# DSPIC33CK256MP506 register map
Vendor: Microchip
Registers are 24-bit, read-write, reset 0xFFFFFF unless marked. A register's access mark holds for its fields unless they carry their own. Addresses are absolute, and some are shared; only a register's first bit layout is shown; [hi:lo] are bit positions; {n}, {i} and the like mark numbered series; 'fields as' and 'values as' point back to an identical list.

## CONFIG — Configuration words, addresses in ProgramSpace
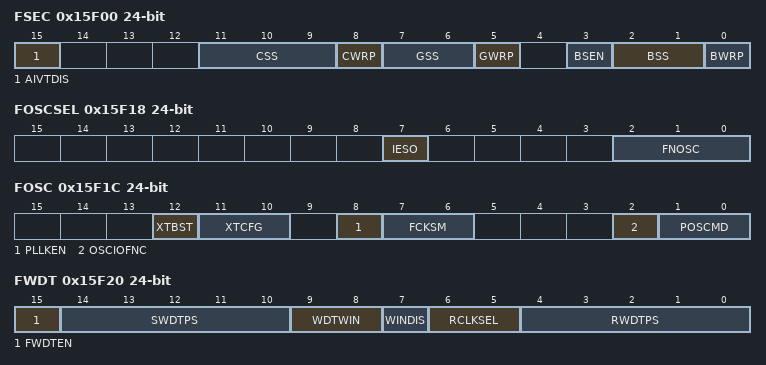
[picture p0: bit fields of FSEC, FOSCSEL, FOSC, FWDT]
0x15F00 FSEC — Security Configuration Options
  [15] AIVTDIS — Alternate Interrupt Vector Table bit
    1=OFF (Disabled AIVT); 0=ON (Enabled AIVT)
  [11:9] CSS — Configuration Segment Code-Protect Level bits
    7=DISABLED (No Protection (other than CWRP)); 6=STNDRD (Standard Security); 4=ENHNCD (Enhanced Security); 0b0xx=HIGH (High Security)
  [8] CWRP — Configuration Segment Write-Protect bit
    1=OFF (Configuration Segment may be written); 0=ON (Configuration Segment is write protected)
  [7:6] GSS — General Segment Code-Protect Level bits
    3=DISABLED (No Protection (other than GWRP)); 2=STNDRD (Standard Security); 0b0x=HIGH (High Security)
  [5] GWRP — General Segment Write-Protect bit
    1=OFF (General Segment may be written); 0=ON (General Segment is write protected)
  [3] BSEN — Boot Segment Control bit
    1=OFF (No Boot Segment); 0=ON (Boot Segment size determined by FBSLIM)
  [2:1] BSS — Boot Segment Code-Protect Level bits
    3=DISABLED (No Protection (other than BWRP)); 2=STNDRD (Standard Security); 0b0x=HIGH (High Security)
  [0] BWRP — Boot Segment Write-Protect bit
    1=OFF (Boot Segment may be written); 0=ON (Boot Segment is write protected)
0x15F10 FBSLIM — Boot Segment Limit Configuration
  [12:0] BSLIM — Boot Segment Flash Page Address Limit bits
0x15F14 FSIGN reset 0xFF7FFF — Sign Bit Configuration
0x15F18 FOSCSEL — Oscillator Configuration 1
  [7] IESO — Two-speed Oscillator Start-up Enable bit
    1=ON (Start up device with FRC, then switch to user-selected oscillator source); 0=OFF (Start up with user-selected oscillator source)
  [2:0] FNOSC — Oscillator Source Selection
    7=FRCDIVN (Internal Fast RC (FRC) Oscillator with postscaler); 6=BFRC (Back up Fast RC (BFRC) Oscillator); 5=LPRC (Low-Power RC Oscillator (LPRC)); 3=PRIPLL (Primary Oscillator with PLL module (XT + PLL, HS + PLL, EC + PLL)); 2=PRI (Primary Oscillator (XT, HS, EC)); 1=FRCPLL (Fast RC Oscillator with divide-by-N with PLL module (FRCPLL)); 0=FRC (Internal Fast RC (FRC))
0x15F1C FOSC — Oscillator Configuration 2
  [12] XTBST — XT Boost
    1=ENABLE (Boost the kick-start); 0=DISABLE (Default kick-start)
  [11:10] XTCFG — XT Config
    0=G0 (4-8 MHz crystals); 1=G1 (8-16 MHz crystals); 2=G2 (16-24 MHz crystals); 3=G3 (24-32 MHz crystals)
  [8] PLLKEN — PLL Lock Status Control
    1=ON (PLL lock signal will be used to disable PLL clock output if lock is lost); 0=OFF (PLL lock signal is not used; the PLL clock output will not be disabled if lock is lost)
  [7:6] FCKSM — Clock Switching Mode bits
    0b1x=CSDCMD (Both Clock switching and Fail-safe Clock Monitor are disabled); 1=CSECMD (Clock switching is enabled,Fail-safe Clock Monitor is disabled); 0=CSECME (Both Clock switching and Fail-safe Clock Monitor are enabled)
  [2] OSCIOFNC — OSC2 Pin Function bit
    1=OFF (OSC2 is clock output); 0=ON (OSC2 is general purpose digital I/O pin)
  [1:0] POSCMD — Primary Oscillator Mode Select bits
    3=NONE (Primary Oscillator disabled); 2=HS (HS Crystal Oscillator Mode); 1=XT (XT Crystal Oscillator Mode); 0=EC (EC (External Clock) Mode)
0x15F20 FWDT — Watch Dog Configuration
  [15] FWDTEN — Watchdog Timer Enable bit
    1=ON (WDT enabled in hardware); 0=ON_SW (WDT controlled via SW, use WDTCON.ON bit)
  [14:10] SWDTPS — Sleep Mode Watchdog Timer Post Scaler select bits
    0=PS1 (1:1); 1=PS2 (1:2); 2=PS4 (1:4); 3=PS8 (1:8); 4=PS16 (1:16); 5=PS32 (1:32); 6=PS64 (1:64); 7=PS128 (1:128); 8=PS256 (1:256); 9=PS512 (1:512); 10=PS1024 (1:1024); 11=PS2048 (1:2048); 12=PS4096 (1:4096); 13=PS8192 (1:8192); 14=PS16384 (1:16384); 15=PS32768 (1:32768); 16=PS65536 (1:65536); 17=PS131072 (1:131072); 18=PS262144 (1:262144); 19=PS524288 (1:524288); 20=PS1048576 (1:1048576); 21=PS2097152 (1:2097152); 22=PS4194304 (1:4194304); 23=PS8388608 (1:8388608); 24=PS16777216 (1:16777216); 25=PS33554432 (1:33554432); 26=PS67108864 (1:67108864); 27=PS134217728 (1:134217728); 28=PS268435456 (1:268435456); 29=PS536870912 (1:536870912); 30=PS1073741824 (1:1073741824); 31=PS2147483648 (1:2147483648)
  [9:8] WDTWIN — Watchdog Timer Window Select bits
    3=WIN25 (WDT Window is 25% of WDT period); 2=WIN37 (WDT Window is 37.5% of WDT period); 1=WIN50 (WDT Window is 50% of WDT period); 0=WIN75 (WDT Windo is 75% of WDT period)
  [7] WINDIS — Watchdog Timer Window Enable bit
    1=ON (Watchdog Timer operates in Non-Window mode); 0=OFF (Watchdog Timer operates in Window mode)
  [6:5] RCLKSEL — Watchdog Timer Clock Select bits
    3=LPRC (Always use LPRC); 2=FRC (Use FRC when WINDIS = 0, system clock is not INTOSC/LPRC and device is not in Sleep;otherwise, use INTOSC/LPRC); 1=FCY (Use peripheral clk when system clock is not INTOSC/LPRC and device is not in Sleep;otherwise, use INTOSC/LPRC)
  [4:0] RWDTPS — Run Mode Watchdog Timer Post Scaler select bits
    values as SWDTPS
0x15F24 FPOR — Power On Configuration
  [6] BISTDIS — Memory BIST Feature Disable
    1=DISABLED (mBIST on reset feature disabled); 0=ENABLED (mBIST on reset feature enabled)
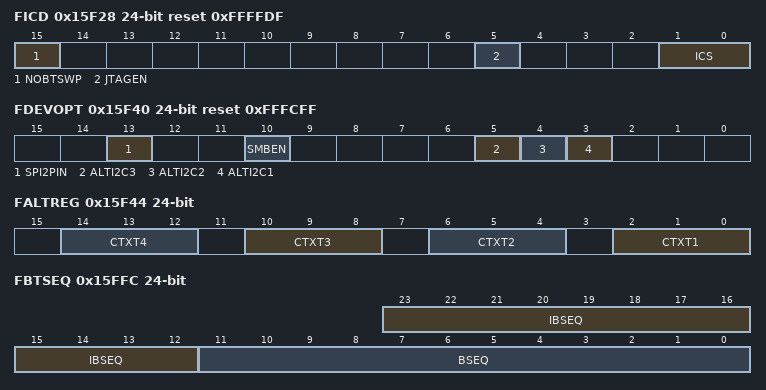
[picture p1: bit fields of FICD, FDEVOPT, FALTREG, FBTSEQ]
0x15F28 FICD reset 0xFFFFDF — ICD Configuration
  [15] NOBTSWP — BOOTSWP instruction disable bit
    1=DISABLED (BOOTSWP instruction is disabled); 0=ENABLED (BOOTSWP instruction is enabled)
  [5] JTAGEN — JTAG Enable bit
    1=ON (JTAG is enabled); 0=OFF (JTAG is disabled)
  [1:0] ICS — ICD Communication Channel Select bits
    3=PGD1 (Communicate on PGC1 and PGD1); 2=PGD2 (Communicate on PGC2 and PGD2); 1=PGD3 (Communicate on PGC3 and PGD3); 0=NONE (Reserved, do not use)
0x15F2C FDMTIVTL — Dead Man Timer Interval low word
  [15:0] DMTIVTL
0x15F30 FDMTIVTH — Dead Man Timer Interval high word
  [15:0] DMTIVTH
0x15F34 FDMTCNTL — Dead man timer instruction count low word
  [15:0] DMTCNTL — Lower 16 bits of 32 bit DMT instruction count time-out value (0-0xFFFF)
0x15F38 FDMTCNTH — Dead man timer instruction count high word
  [15:0] DMTCNTH — Upper 16 bits of 32 bit DMT instruction count time-out value (0-0xFFFF)
0x15F3C FDMT — Dead Man Timer configuration
  [0] DMTDIS — Dead Man Timer Disable bit
    1=OFF (Dead Man Timer is Disabled and can be enabled by software); 0=ON (Dead Man Timer is Enabled and cannot be disabled by software)
0x15F40 FDEVOPT reset 0xFFFCFF — Device Configuration options
  [13] SPI2PIN — SPI2 Pin Select bit
    1=PPS (SPI2 uses I/O remap (PPS) pins); 0=DEDICATED (SPI2 uses dedicated I/O pins)
  [10] SMBEN — SM Bus Enable
    1=SMBUS (SMBus input threshold is enabled); 0=STANDARD (Standard I2C input threshold operation)
  [5] ALTI2C3 — Alternate I2C3 Pin bit
    1=OFF (I2C3 mapped to SDA3/SCL3 pins); 0=ON (I2C3 mapped to ASDA3/ASCL3 pins)
  [4] ALTI2C2 — Alternate I2C2 Pin bit
    1=OFF (I2C2 mapped to SDA2/SCL2 pins); 0=ON (I2C2 mapped to ASDA2/ASCL2 pins)
  [3] ALTI2C1 — Alternate I2C1 Pin bit
    1=OFF (I2C1 mapped to SDA1/SCL1 pins); 0=ON (I2C1 mapped to ASDA1/ASCL1 pins)
0x15F44 FALTREG — Alternate W-Reg Configuration
  [all] fields
    7=OFF (Not Assigned); {v}=IPL{v+1} (Alternate Register set assigned to IPL level {v+1}) (v=0..6)
  [4n-2:4n-4] CTXT{n} (n=1..4) — Specifies Interrupt Priority Level (IPL) Associated to Alternate Working Register {n} bits
0x15FFC FBTSEQ — Boot Sequence Configuration Register
  [23:12] IBSEQ — The one's complement of BSEQ; must be calculated by the user and written during device programming.
  [11:0] BSEQ — Relative value defining which partition will be active after device Reset; the partition containing a lower boot number will be active
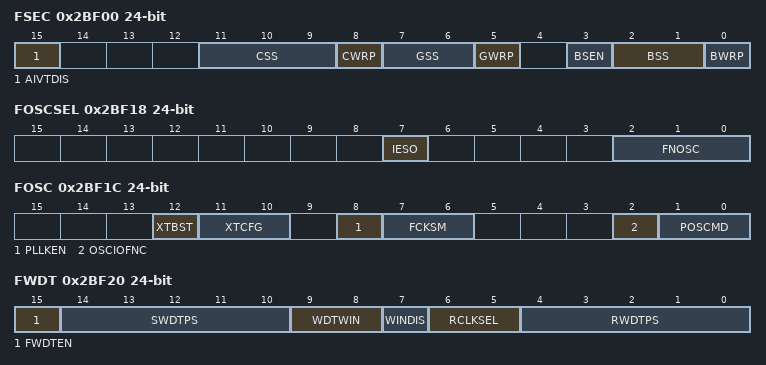
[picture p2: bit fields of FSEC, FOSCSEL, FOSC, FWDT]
0x2BF00 FSEC — Security Configuration Options
  fields as FSEC
0x2BF10 FBSLIM — Boot Segment Limit Configuration
  [12:0] BSLIM — Boot Segment Flash Page Address Limit bits
0x2BF14 FSIGN reset 0xFF7FFF — Sign Bit Configuration
0x2BF18 FOSCSEL — Oscillator Configuration 1
  fields as FOSCSEL
0x2BF1C FOSC — Oscillator Configuration 2
  fields as FOSC
0x2BF20 FWDT — Watch Dog Configuration
  fields as FWDT
0x2BF24 FPOR — Power On Configuration
  fields as FPOR
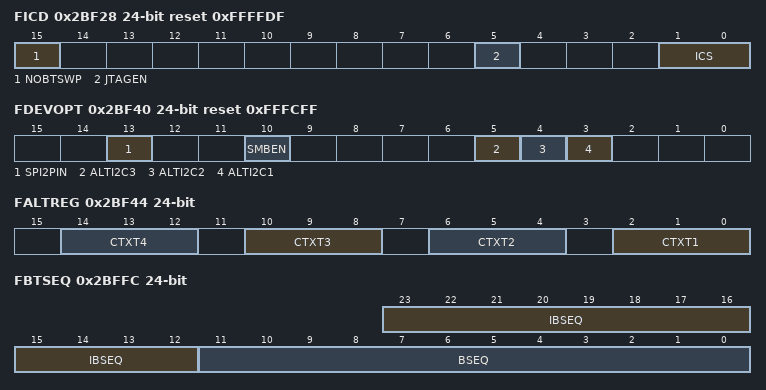
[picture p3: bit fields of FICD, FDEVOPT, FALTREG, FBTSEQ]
0x2BF28 FICD reset 0xFFFFDF — ICD Configuration
  fields as FICD
0x2BF2C FDMTIVTL — Dead Man Timer Interval low word
  [15:0] DMTIVTL
0x2BF30 FDMTIVTH — Dead Man Timer Interval high word
  [15:0] DMTIVTH
0x2BF34 FDMTCNTL — Dead man timer instruction count low word
  fields as FDMTCNTL
0x2BF38 FDMTCNTH — Dead man timer instruction count high word
  fields as FDMTCNTH
0x2BF3C FDMT — Dead Man Timer configuration
  fields as FDMT
0x2BF40 FDEVOPT reset 0xFFFCFF — Device Configuration options
  fields as FDEVOPT
0x2BF44 FALTREG — Alternate W-Reg Configuration
  fields as FALTREG
0x2BFFC FBTSEQ — Boot Sequence Configuration Register
  fields as FBTSEQ
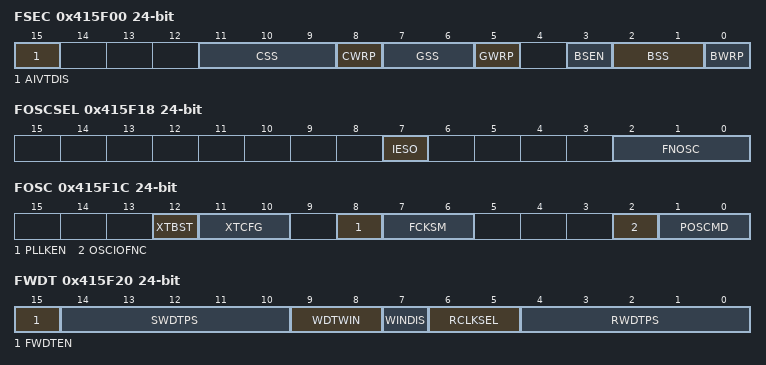
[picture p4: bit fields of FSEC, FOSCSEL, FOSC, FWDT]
0x415F00 FSEC — Security Configuration Options
  fields as FSEC
0x415F10 FBSLIM — Boot Segment Limit Configuration
  [12:0] BSLIM — Boot Segment Flash Page Address Limit bits
0x415F14 FSIGN reset 0xFF7FFF — Sign Bit Configuration
0x415F18 FOSCSEL — Oscillator Configuration 1
  fields as FOSCSEL
0x415F1C FOSC — Oscillator Configuration 2
  fields as FOSC
0x415F20 FWDT — Watch Dog Configuration
  fields as FWDT
0x415F24 FPOR — Power On Configuration
  fields as FPOR
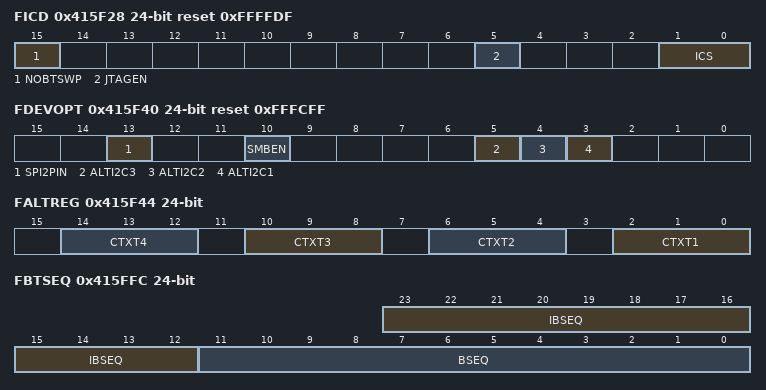
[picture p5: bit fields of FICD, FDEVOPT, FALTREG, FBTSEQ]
0x415F28 FICD reset 0xFFFFDF — ICD Configuration
  fields as FICD
0x415F2C FDMTIVTL — Dead Man Timer Interval low word
  [15:0] DMTIVTL
0x415F30 FDMTIVTH — Dead Man Timer Interval high word
  [15:0] DMTIVTH
0x415F34 FDMTCNTL — Dead man timer instruction count low word
  fields as FDMTCNTL
0x415F38 FDMTCNTH — Dead man timer instruction count high word
  fields as FDMTCNTH
0x415F3C FDMT — Dead Man Timer configuration
  fields as FDMT
0x415F40 FDEVOPT reset 0xFFFCFF — Device Configuration options
  fields as FDEVOPT
0x415F44 FALTREG — Alternate W-Reg Configuration
  fields as FALTREG
0x415FFC FBTSEQ — Boot Sequence Configuration Register
  fields as FBTSEQ
0x801800 FBOOT — Device Boot Configuration Register
  [1:0] BTMODE — Device Boot Mode Configuration
    3=SINGLE (Device is in Single Boot (legacy) mode); 2=DUAL (Device is in Dual Partition mode); 1=DUALPROT (Device is in Dual Partition Protected mode); 0=DUALPRIV (Device is in Dual Partition Privilege mode)
